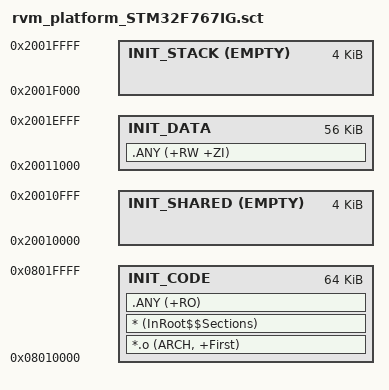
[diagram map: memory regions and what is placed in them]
;******************************************************************************
;Filename    : rvm_platform_STM32F767IG.sct
;Author      : pry
;Date        : 24/06/2017
;Licence     : The Unlicense; see LICENSE for details.
;Description : The scatter file for Cortex-M7 init process layout. This file is
;              intended to be used with STM32F767IGT6.
;              Init ROM layout:
;              |0x08010000                                          0x0801FFFF|
;              |<-                            Init                          ->|
;              Init RAM layout:
;              |0x20010000            0x2001EFFF|0x2001F000         0x2001FFFF|
;              |<-         Init Data          ->|<-       Init Stack        ->|
;******************************************************************************
INIT 0x08010000 0x00010000
{   
    ; Process code segment - 64kB
    INIT_CODE 0x08010000 0x00010000
    {   ; The entry will be the first instruction
        *.o                    (ARCH, +First)
        ; The lib code copying code
        *                      (InRoot$$Sections)
        ; The init code section
        .ANY                   (+RO)
    }
    
    ; Interrupt flag & other shared data region - 4kB total
    INIT_SHARED 0x20010000 EMPTY 0x00001000
    {
    
    }
    
    ; The data section of the INIT process - 56kB total
    INIT_DATA 0x20011000 0x0000E000
    {
        .ANY                   (+RW +ZI)
    }
    
    ; The initial stack section of the INIT process - 4kB total.
    INIT_STACK 0x2001F000 EMPTY 0x00001000
    {
        /* Place the stack array here */
    }
}
; End Of File *****************************************************************

; Copyright (C) Evo-Devo Instrum. All rights reserved *************************

